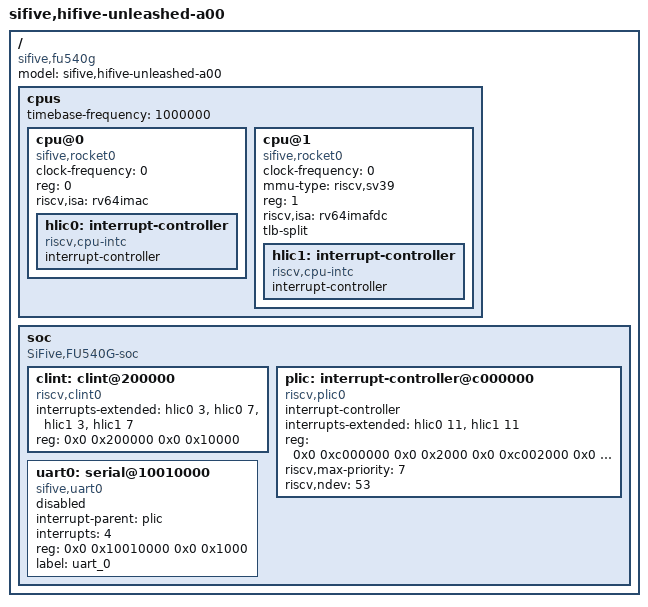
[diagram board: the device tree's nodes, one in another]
/* SPDX-License-Identifier: Apache-2.0 */

#include <dt-bindings/gpio/gpio.h>

/ {
	#address-cells = <2>;
	#size-cells = <2>;
	compatible = "sifive,fu540g", "sifive,fu500";
	model = "sifive,hifive-unleashed-a00";

	cpus {
		#address-cells = <1>;
		#size-cells = <0>;
		timebase-frequency = <1000000>;
		cpu@0 {
			clock-frequency = <0>;
			compatible = "sifive,rocket0", "riscv";
			device_type = "cpu";
			reg = <0>;
			riscv,isa = "rv64imac";
			status = "okay";
			hlic0: interrupt-controller {
				#interrupt-cells = <1>;
				compatible = "riscv,cpu-intc";
				interrupt-controller;
			};
		};
		cpu@1 {
			clock-frequency = <0>;
			compatible = "sifive,rocket0", "riscv";
			device_type = "cpu";
			mmu-type = "riscv,sv39";
			reg = <1>;
			riscv,isa = "rv64imafdc";
			status = "okay";
			tlb-split;
			hlic1: interrupt-controller {
				#interrupt-cells = <1>;
				compatible = "riscv,cpu-intc";
				interrupt-controller;
			};
		};
	};

	soc {
		#address-cells = <2>;
		#size-cells = <2>;
		compatible = "SiFive,FU540G-soc", "fu500-soc", "sifive-soc", "simple-bus";
		ranges;

		clint: clint@200000 {
			compatible = "riscv,clint0";
			interrupts-extended = <&hlic0 3 &hlic0 7 &hlic1 3 &hlic1 7>;
			reg = <0x0 0x200000 0x0 0x10000>;
			reg-names = "control";
		};

		plic: interrupt-controller@c000000 {
			#interrupt-cells = <1>;
			compatible = "riscv,plic0";
			interrupt-controller;
			interrupts-extended = <&hlic0 11 &hlic1 11>;
			reg = <0x0 0xc000000 0x0 0x2000
			       0x0 0xc002000 0x0 0x1fe000
			       0x0 0xc200000 0x0 0x2000000>;
			reg-names = "prio", "irq_en", "reg";
			riscv,max-priority = <7>;
			riscv,ndev = <53>;
		};

		uart0: serial@10010000 {
			compatible = "sifive,uart0";
			interrupt-parent = <&plic>;
			interrupts = <4>;
			reg = <0x0 0x10010000 0x0 0x1000>;
			reg-names = "control";
			label = "uart_0";
			status = "disabled";
		};
	};
};
